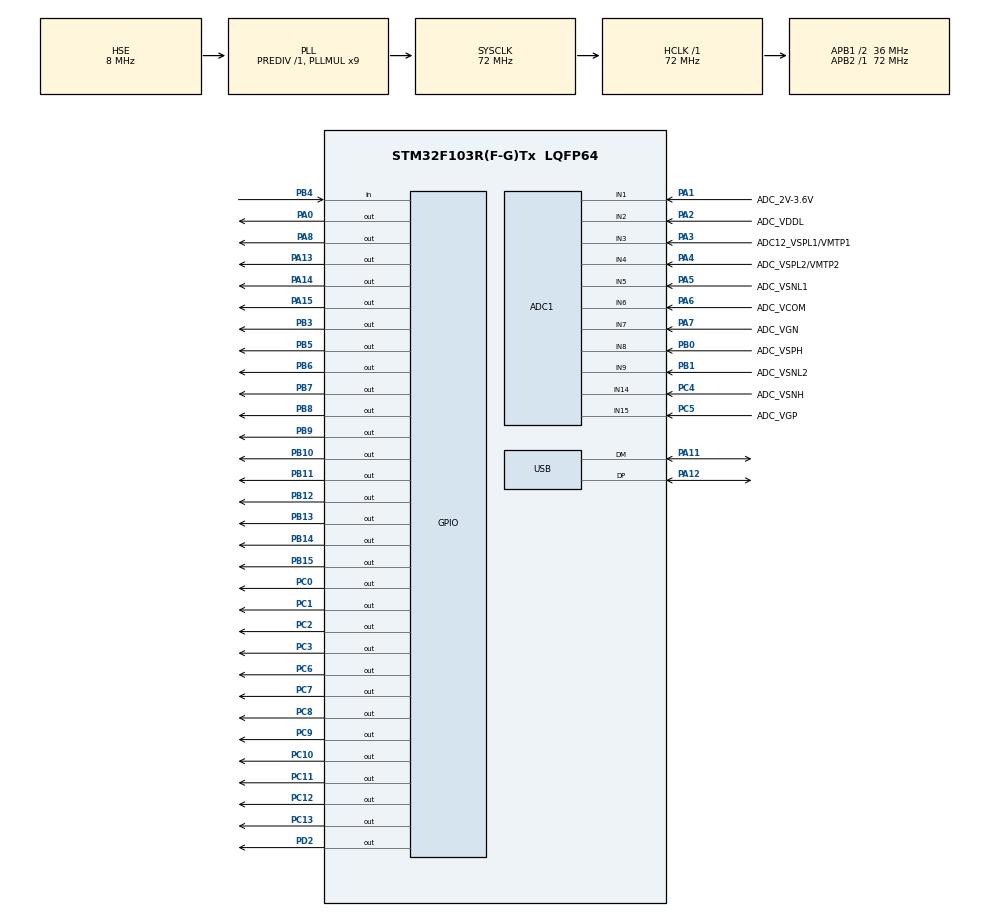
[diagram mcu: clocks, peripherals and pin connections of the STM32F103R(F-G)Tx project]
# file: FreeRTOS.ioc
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ADC1.Channel-0\#ChannelRegularConversion=ADC_CHANNEL_1
ADC1.Channel-1\#ChannelRegularConversion=ADC_CHANNEL_2
ADC1.Channel-10\#ChannelRegularConversion=ADC_CHANNEL_15
ADC1.Channel-2\#ChannelRegularConversion=ADC_CHANNEL_3
ADC1.Channel-3\#ChannelRegularConversion=ADC_CHANNEL_4
ADC1.Channel-4\#ChannelRegularConversion=ADC_CHANNEL_5
ADC1.Channel-5\#ChannelRegularConversion=ADC_CHANNEL_6
ADC1.Channel-6\#ChannelRegularConversion=ADC_CHANNEL_7
ADC1.Channel-7\#ChannelRegularConversion=ADC_CHANNEL_8
ADC1.Channel-8\#ChannelRegularConversion=ADC_CHANNEL_9
ADC1.Channel-9\#ChannelRegularConversion=ADC_CHANNEL_14
ADC1.ContinuousConvMode=DISABLE
ADC1.NbrOfConversion=11
ADC1.NbrOfConversionFlag=1
ADC1.Rank-0\#ChannelRegularConversion=1
ADC1.Rank-1\#ChannelRegularConversion=2
ADC1.Rank-10\#ChannelRegularConversion=11
ADC1.Rank-2\#ChannelRegularConversion=3
ADC1.Rank-3\#ChannelRegularConversion=4
ADC1.Rank-4\#ChannelRegularConversion=5
ADC1.Rank-5\#ChannelRegularConversion=6
ADC1.Rank-6\#ChannelRegularConversion=7
ADC1.Rank-7\#ChannelRegularConversion=8
ADC1.Rank-8\#ChannelRegularConversion=9
ADC1.Rank-9\#ChannelRegularConversion=10
ADC1.SamplingTime-0\#ChannelRegularConversion=ADC_SAMPLETIME_239CYCLES_5
ADC1.SamplingTime-1\#ChannelRegularConversion=ADC_SAMPLETIME_239CYCLES_5
ADC1.SamplingTime-10\#ChannelRegularConversion=ADC_SAMPLETIME_239CYCLES_5
ADC1.SamplingTime-2\#ChannelRegularConversion=ADC_SAMPLETIME_239CYCLES_5
ADC1.SamplingTime-3\#ChannelRegularConversion=ADC_SAMPLETIME_239CYCLES_5
ADC1.SamplingTime-4\#ChannelRegularConversion=ADC_SAMPLETIME_239CYCLES_5
ADC1.SamplingTime-5\#ChannelRegularConversion=ADC_SAMPLETIME_239CYCLES_5
ADC1.SamplingTime-6\#ChannelRegularConversion=ADC_SAMPLETIME_239CYCLES_5
ADC1.SamplingTime-7\#ChannelRegularConversion=ADC_SAMPLETIME_239CYCLES_5
ADC1.SamplingTime-8\#ChannelRegularConversion=ADC_SAMPLETIME_239CYCLES_5
ADC1.SamplingTime-9\#ChannelRegularConversion=ADC_SAMPLETIME_239CYCLES_5
ADC1.master=1
Dma.ADC1.0.Direction=DMA_PERIPH_TO_MEMORY
Dma.ADC1.0.Instance=DMA1_Channel1
Dma.ADC1.0.MemDataAlignment=DMA_MDATAALIGN_WORD
Dma.ADC1.0.MemInc=DMA_MINC_ENABLE
Dma.ADC1.0.Mode=DMA_NORMAL
Dma.ADC1.0.PeriphDataAlignment=DMA_PDATAALIGN_WORD
Dma.ADC1.0.PeriphInc=DMA_PINC_DISABLE
Dma.ADC1.0.Priority=DMA_PRIORITY_MEDIUM
Dma.Request0=ADC1
FREERTOS.Tasks01=defaultTask,24,128,StartDefaultTask,Default,NULL,Dynamic,NULL,NULL
Mcu.Family=STM32F1
Mcu.Name=STM32F103R(F-G)Tx
Mcu.Package=LQFP64
NVIC.DMA1_Channel1_IRQn=true\:5\:0\:false\:false\:true\:true\:false\:true\:true
NVIC.PriorityGroup=NVIC_PRIORITYGROUP_4
NVIC.TIM6_IRQn=true\:15\:0\:false\:false\:true\:false\:false\:true\:true
NVIC.TimeBase=TIM6_IRQn
NVIC.TimeBaseIP=TIM6
NVIC.USB_LP_CAN1_RX0_IRQn=true\:5\:0\:false\:false\:true\:true\:false\:true\:true
PA0-WKUP.GPIO_ModeDefaultOutputPP=GPIO_MODE_OUTPUT_PP
PA0-WKUP.GPIO_PuPd=GPIO_PULLDOWN
PA0-WKUP.GPIO_Speed=GPIO_SPEED_FREQ_HIGH
PA0-WKUP.PinState=GPIO_PIN_RESET
PA0-WKUP.Signal=GPIO_Output
PA1.GPIO_Label=ADC_2V-3.6V
PA1.Signal=ADCx_IN1
PA11.Mode=Device
PA11.Signal=USB_DM
PA12.Mode=Device
PA12.Signal=USB_DP
PA13.GPIO_PuPd=GPIO_PULLDOWN
PA13.GPIO_Speed=GPIO_SPEED_FREQ_HIGH
PA13.Signal=GPIO_Output
PA14.GPIO_PuPd=GPIO_PULLDOWN
PA14.GPIO_Speed=GPIO_SPEED_FREQ_HIGH
PA14.Signal=GPIO_Output
PA15.GPIO_PuPd=GPIO_PULLDOWN
PA15.GPIO_Speed=GPIO_SPEED_FREQ_HIGH
PA15.Signal=GPIO_Output
PA2.GPIO_Label=ADC_VDDL
PA2.Signal=ADCx_IN2
PA3.GPIO_Label=ADC12_VSPL1/VMTP1
PA3.Signal=ADCx_IN3
PA4.GPIO_Label=ADC_VSPL2/VMTP2
PA4.Signal=ADCx_IN4
PA5.GPIO_Label=ADC_VSNL1
PA5.Signal=ADCx_IN5
PA6.GPIO_Label=ADC_VCOM
PA6.Signal=ADCx_IN6
PA7.GPIO_Label=ADC_VGN
PA7.Signal=ADCx_IN7
PA8.GPIO_PuPd=GPIO_PULLUP
PA8.GPIO_Speed=GPIO_SPEED_FREQ_HIGH
PA8.PinState=GPIO_PIN_SET
PA8.Signal=GPIO_Output
PB0.GPIO_Label=ADC_VSPH
PB0.Signal=ADCx_IN8
PB1.GPIO_Label=ADC_VSNL2
PB1.Signal=ADCx_IN9
PB10.GPIO_ModeDefaultOutputPP=GPIO_MODE_OUTPUT_PP
PB10.GPIO_PuPd=GPIO_PULLDOWN
PB10.GPIO_Speed=GPIO_SPEED_FREQ_HIGH
PB10.PinState=GPIO_PIN_RESET
PB10.Signal=GPIO_Output
PB11.GPIO_PuPd=GPIO_PULLDOWN
PB11.GPIO_Speed=GPIO_SPEED_FREQ_HIGH
PB11.Signal=GPIO_Output
PB12.GPIO_PuPd=GPIO_PULLDOWN
PB12.GPIO_Speed=GPIO_SPEED_FREQ_HIGH
PB12.Signal=GPIO_Output
PB13.GPIO_PuPd=GPIO_PULLDOWN
PB13.GPIO_Speed=GPIO_SPEED_FREQ_HIGH
PB13.Signal=GPIO_Output
PB14.GPIO_PuPd=GPIO_PULLDOWN
PB14.GPIO_Speed=GPIO_SPEED_FREQ_HIGH
PB14.Signal=GPIO_Output
PB15.GPIO_PuPd=GPIO_PULLDOWN
PB15.GPIO_Speed=GPIO_SPEED_FREQ_HIGH
PB15.Signal=GPIO_Output
PB3.GPIO_ModeDefaultOutputPP=GPIO_MODE_OUTPUT_PP
PB3.GPIO_PuPd=GPIO_PULLUP
PB3.GPIO_Speed=GPIO_SPEED_FREQ_HIGH
PB3.PinState=GPIO_PIN_SET
PB3.Signal=GPIO_Output
PB4.Signal=GPIO_Input
PB5.GPIO_PuPd=GPIO_PULLDOWN
PB5.GPIO_Speed=GPIO_SPEED_FREQ_HIGH
PB5.Signal=GPIO_Output
PB6.GPIO_PuPd=GPIO_PULLDOWN
PB6.GPIO_Speed=GPIO_SPEED_FREQ_HIGH
PB6.Signal=GPIO_Output
PB7.GPIO_PuPd=GPIO_PULLDOWN
PB7.GPIO_Speed=GPIO_SPEED_FREQ_HIGH
PB7.Signal=GPIO_Output
PB8.GPIO_PuPd=GPIO_PULLDOWN
PB8.GPIO_Speed=GPIO_SPEED_FREQ_HIGH
PB8.Signal=GPIO_Output
PB9.GPIO_PuPd=GPIO_PULLDOWN
PB9.GPIO_Speed=GPIO_SPEED_FREQ_HIGH
PB9.Signal=GPIO_Output
PC0.GPIO_ModeDefaultOutputPP=GPIO_MODE_OUTPUT_PP
PC0.GPIO_PuPd=GPIO_PULLDOWN
PC0.GPIO_Speed=GPIO_SPEED_FREQ_HIGH
PC0.Signal=GPIO_Output
PC1.GPIO_ModeDefaultOutputPP=GPIO_MODE_OUTPUT_PP
PC1.GPIO_PuPd=GPIO_PULLDOWN
PC1.GPIO_Speed=GPIO_SPEED_FREQ_HIGH
PC1.Signal=GPIO_Output
PC10.GPIO_ModeDefaultOutputPP=GPIO_MODE_OUTPUT_PP
PC10.GPIO_PuPd=GPIO_PULLUP
PC10.PinState=GPIO_PIN_SET
PC10.Signal=GPIO_Output
PC11.GPIO_ModeDefaultOutputPP=GPIO_MODE_OUTPUT_PP
PC11.GPIO_PuPd=GPIO_PULLUP
PC11.GPIO_Speed=GPIO_SPEED_FREQ_HIGH
PC11.PinState=GPIO_PIN_SET
PC11.Signal=GPIO_Output
PC12.GPIO_ModeDefaultOutputPP=GPIO_MODE_OUTPUT_PP
PC12.GPIO_PuPd=GPIO_PULLUP
PC12.GPIO_Speed=GPIO_SPEED_FREQ_HIGH
PC12.PinState=GPIO_PIN_SET
PC12.Signal=GPIO_Output
PC13-TAMPER-RTC.GPIO_ModeDefaultOutputPP=GPIO_MODE_OUTPUT_PP
PC13-TAMPER-RTC.GPIO_PuPd=GPIO_PULLUP
PC13-TAMPER-RTC.GPIO_Speed=GPIO_SPEED_FREQ_HIGH
PC13-TAMPER-RTC.PinState=GPIO_PIN_SET
PC13-TAMPER-RTC.Signal=GPIO_Output
PC14-OSC32_IN.Mode=LSE-External-Oscillator
PC14-OSC32_IN.Signal=RCC_OSC32_IN
PC15-OSC32_OUT.Mode=LSE-External-Oscillator
PC15-OSC32_OUT.Signal=RCC_OSC32_OUT
PC2.GPIO_ModeDefaultOutputPP=GPIO_MODE_OUTPUT_OD
PC2.GPIO_PuPd=GPIO_NOPULL
PC2.GPIO_Speed=GPIO_SPEED_FREQ_HIGH
PC2.PinState=GPIO_PIN_SET
PC2.Signal=GPIO_Output
PC3.GPIO_ModeDefaultOutputPP=GPIO_MODE_OUTPUT_OD
PC3.GPIO_PuPd=GPIO_NOPULL
PC3.GPIO_Speed=GPIO_SPEED_FREQ_HIGH
PC3.PinState=GPIO_PIN_SET
PC3.Signal=GPIO_Output
PC4.GPIO_Label=ADC_VSNH
PC4.Signal=ADCx_IN14
PC5.GPIO_Label=ADC_VGP
PC5.Signal=ADCx_IN15
PC6.GPIO_PuPd=GPIO_PULLDOWN
PC6.GPIO_Speed=GPIO_SPEED_FREQ_HIGH
PC6.Signal=GPIO_Output
PC7.GPIO_ModeDefaultOutputPP=GPIO_MODE_OUTPUT_PP
PC7.GPIO_PuPd=GPIO_PULLUP
PC7.GPIO_Speed=GPIO_SPEED_FREQ_HIGH
PC7.PinState=GPIO_PIN_SET
PC7.Signal=GPIO_Output
PC8.GPIO_PuPd=GPIO_PULLUP
PC8.GPIO_Speed=GPIO_SPEED_FREQ_HIGH
PC8.PinState=GPIO_PIN_SET
PC8.Signal=GPIO_Output
PC9.GPIO_ModeDefaultOutputPP=GPIO_MODE_OUTPUT_PP
PC9.GPIO_PuPd=GPIO_PULLUP
PC9.GPIO_Speed=GPIO_SPEED_FREQ_HIGH
PC9.PinState=GPIO_PIN_SET
PC9.Signal=GPIO_Output
PD0-OSC_IN.Mode=HSE-External-Oscillator
PD0-OSC_IN.Signal=RCC_OSC_IN
PD1-OSC_OUT.Mode=HSE-External-Oscillator
PD1-OSC_OUT.Signal=RCC_OSC_OUT
PD2.GPIO_ModeDefaultOutputPP=GPIO_MODE_OUTPUT_PP
PD2.GPIO_PuPd=GPIO_PULLUP
PD2.GPIO_Speed=GPIO_SPEED_FREQ_HIGH
PD2.PinState=GPIO_PIN_SET
PD2.Signal=GPIO_Output
ProjectManager.HeapSize=0x1000
ProjectManager.StackSize=0x1000
ProjectManager.TargetToolchain=Makefile
RCC.ADCPresc=RCC_ADCPCLK2_DIV6
RCC.AHBFreq_Value=72000000
RCC.APB1CLKDivider=RCC_HCLK_DIV2
RCC.APB1Freq_Value=36000000
RCC.APB1TimFreq_Value=72000000
RCC.APB2Freq_Value=72000000
RCC.APB2TimFreq_Value=72000000
RCC.HCLKFreq_Value=72000000
RCC.PLLMUL=RCC_PLL_MUL9
RCC.SYSCLKFreq_VALUE=72000000
RCC.SYSCLKSource=RCC_SYSCLKSOURCE_PLLCLK
RCC.USBFreq_Value=48000000
RCC.USBPrescaler=RCC_USBCLKSOURCE_PLL_DIV1_5
SH.ADCx_IN1.0=ADC1_IN1,IN1
SH.ADCx_IN14.0=ADC1_IN14,IN14
SH.ADCx_IN15.0=ADC1_IN15,IN15
SH.ADCx_IN2.0=ADC1_IN2,IN2
SH.ADCx_IN3.0=ADC1_IN3,IN3
SH.ADCx_IN4.0=ADC1_IN4,IN4
SH.ADCx_IN5.0=ADC1_IN5,IN5
SH.ADCx_IN6.0=ADC1_IN6,IN6
SH.ADCx_IN7.0=ADC1_IN7,IN7
SH.ADCx_IN8.0=ADC1_IN8,IN8
SH.ADCx_IN9.0=ADC1_IN9,IN9
USB_DEVICE.CLASS_NAME_FS=CDC
USB_DEVICE.VirtualMode=Cdc
USB_DEVICE.VirtualModeFS=Cdc_FS
VP_CRC_VS_CRC.Mode=CRC_Activate
VP_FREERTOS_VS_CMSIS_V2.Mode=CMSIS_V2
VP_SYS_VS_ND.Mode=No_Debug
VP_SYS_VS_tim6.Mode=TIM6
VP_USB_DEVICE_VS_USB_DEVICE_CDC_FS.Mode=CDC_FS
board=custom

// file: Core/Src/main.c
/* USER CODE BEGIN Header */
/**
  ******************************************************************************
  * @file           : main.c
  * @brief          : Main program body
  ******************************************************************************
  * @attention
  *
  * Copyright (c) 2025 STMicroelectronics.
  * All rights reserved.
  *
  * This software is licensed under terms that can be found in the LICENSE file
  * in the root directory of this software component.
  * If no LICENSE file comes with this software, it is provided AS-IS.
  *
  ******************************************************************************
  */
/* USER CODE END Header */
#include "main.h"
#include "cmsis_os.h"
#include "adc.h"
#include "dma.h"
#include "gpio.h"

/* USER CODE BEGIN Includes */
#include "ReceiveDataProcess.h"
#include "SendDataProcess.h"
#include "ADCAPP.h"
#include "TaskList.h"
#include "uart1.h"
#include "HWCIDri.h"
#include "DPPTM.h"
/* USER CODE END Includes */

void SystemClock_Config(void);
void MX_FREERTOS_Init(void);

int main(void)
{

  /* MCU Configuration--------------------------------------------------------*/

  /* Reset of all peripherals, Initializes the Flash interface and the Systick. */
  HAL_Init();

  /* Configure the system clock */
  SystemClock_Config();

  /* Initialize all configured peripherals */
  MX_GPIO_Init();
  MX_DMA_Init();
  MX_ADC1_Init();
  UART1_Init();
  /* USER CODE BEGIN 2 */

  vCreateReceiveDataTask();
  vCreateSendDataTask();
  vCreateHWCIProcessTask();
  vCreateADCTask();

  /* USER CODE END 2 */

  /* Init scheduler */
  osKernelInitialize();  /* Call init function for freertos objects (in cmsis_os2.c) */
  MX_FREERTOS_Init();

  /* Start scheduler */
  osKernelStart();

  /* We should never get here as control is now taken by the scheduler */

  /* Infinite loop */
  while (1)
  {

  }
}

void SystemClock_Config(void)
{
  RCC_OscInitTypeDef RCC_OscInitStruct = {0};
  RCC_ClkInitTypeDef RCC_ClkInitStruct = {0};
  RCC_PeriphCLKInitTypeDef PeriphClkInit = {0};

  /** Initializes the RCC Oscillators according to the specified parameters
  * in the RCC_OscInitTypeDef structure.
  */
  RCC_OscInitStruct.OscillatorType = RCC_OSCILLATORTYPE_HSE;
  RCC_OscInitStruct.HSEState = RCC_HSE_ON;
  RCC_OscInitStruct.HSEPredivValue = RCC_HSE_PREDIV_DIV1;
  RCC_OscInitStruct.HSIState = RCC_HSI_ON;
  RCC_OscInitStruct.PLL.PLLState = RCC_PLL_ON;
  RCC_OscInitStruct.PLL.PLLSource = RCC_PLLSOURCE_HSE;
  RCC_OscInitStruct.PLL.PLLMUL = RCC_PLL_MUL9;
  if (HAL_RCC_OscConfig(&RCC_OscInitStruct) != HAL_OK)
  {
    Error_Handler();
  }

  /** Initializes the CPU, AHB and APB buses clocks
  */
  RCC_ClkInitStruct.ClockType = RCC_CLOCKTYPE_HCLK|RCC_CLOCKTYPE_SYSCLK
                              |RCC_CLOCKTYPE_PCLK1|RCC_CLOCKTYPE_PCLK2;
  RCC_ClkInitStruct.SYSCLKSource = RCC_SYSCLKSOURCE_PLLCLK;
  RCC_ClkInitStruct.AHBCLKDivider = RCC_SYSCLK_DIV1;
  RCC_ClkInitStruct.APB1CLKDivider = RCC_HCLK_DIV2;
  RCC_ClkInitStruct.APB2CLKDivider = RCC_HCLK_DIV1;

  if (HAL_RCC_ClockConfig(&RCC_ClkInitStruct, FLASH_LATENCY_2) != HAL_OK)
  {
    Error_Handler();
  }
  PeriphClkInit.PeriphClockSelection = RCC_PERIPHCLK_ADC|RCC_PERIPHCLK_USB;
  PeriphClkInit.AdcClockSelection = RCC_ADCPCLK2_DIV6;
  PeriphClkInit.UsbClockSelection = RCC_USBCLKSOURCE_PLL_DIV1_5;
  if (HAL_RCCEx_PeriphCLKConfig(&PeriphClkInit) != HAL_OK)
  {
    Error_Handler();
  }
}

void HAL_TIM_PeriodElapsedCallback(TIM_HandleTypeDef *htim)
{
  if (htim->Instance == TIM6)
  {
    HAL_IncTick();
  }
}

void Error_Handler(void)
{
  __disable_irq();
  while (1)
  {
  }
}
